VERSION ""

NS_ :

BS_:

BU_: DCU ACM
VAL_TABLE_ J1939_8bit 255 "Not Available" 254 "Fault" 253 "Reserved" 252 "Reserved" 251 "Reserved" ;
VAL_TABLE_ EDR_eCall_Active 7 "Not available" 6 "Fault" 5 "Reserved" 4 "Reserved" 3 "Reserved" 2 "On - eCall triggered" 1 "On - eCall not triggered" 0 "Off" ;
VAL_TABLE_ EDR_LwdsState 7 "Not available" 6 "Fault" 5 "Reserved" 4 "Reserved" 3 "Warning Right" 2 "Warning Left" 1 "On but not warning" 0 "Off" ;
VAL_TABLE_ EDR_Cruise_Control_Active 7 "Not Available" 6 "Fault" 5 "Reserved" 4 "Reserved" 3 "Reserved" 2 "On but not controlling" 1 "Activly Controlling" 0 "Off" ;
VAL_TABLE_ EDR_TPMSLampState 3 "Fault" 2 "Lamp Flashing" 1 "Lamp On" 0 "Lamp Off" ;
VAL_TABLE_ EDR_StrWhAng 65535 "sna" 65534 "error" ;
VAL_TABLE_ EDR_AEbState 15 "na / not installed" 14 "error indication" 8 "sys perf and/or sensitivity ltd" 7 "emergency braking active" 6 "collision warning with braking" 5 "collision warning active" 4 "driver overrides system" 3 "ready and activated" 2 "sys ready and activated" 1 "sys temp NA" 0 "sys not ready" ;
VAL_TABLE_ EDR_TCsStatus 3 "TCS off - TCS failure" 2 "Veh not equipped with TCS" 1 " TCS OFF system passive request" 0 "TCS fully available" ;
VAL_TABLE_ EDR_TCsActive 1 "TCs interv by ESP sys MFL ON" 0 "No TCs intervention MFL OFF" ;
VAL_TABLE_ EDR_ESpStatus 3 "ESP off - ESP failure" 2 "Veh not equipped with ESP" 1 "ESP OFF system passive request" 0 "ESP fully available" ;
VAL_TABLE_ EDR_ESpActive 1 "ESP interv actv MFL is BLINKING" 0 "No ESP intervention MFL OFF" ;
VAL_TABLE_ EDR_ABsStatus 2 "ABS off -  failure at ABS/ESP" 0 "ABS fully available" ;
VAL_TABLE_ EDR_ABsActive 1 "ABS intrvntn by ABS/ESP is actv" 0 "No ABS intervention by ABS/ESP" ;
VAL_TABLE_ EDR_AirbagLampState 2 "Not Available" 1 "Airbag Warning Lamp On" 0 "No Lamp" ;
VAL_TABLE_ EDR_RecupBrakeState 1 "Recuperation Enable" 0 "Recuperation Disable" ;
VAL_TABLE_ EDR_BrakePedalPressed 3 "Faulty" 2 "PedalPressed" 1 "NotPressed" 0 "NotUsed" ;

BO_ 3221225472 VECTOR__INDEPENDENT_SIG_MSG: 0 Vector__XXX
 SG_ TCSActive : 0|2@1+ (1,0) [0|1] "" Vector__XXX

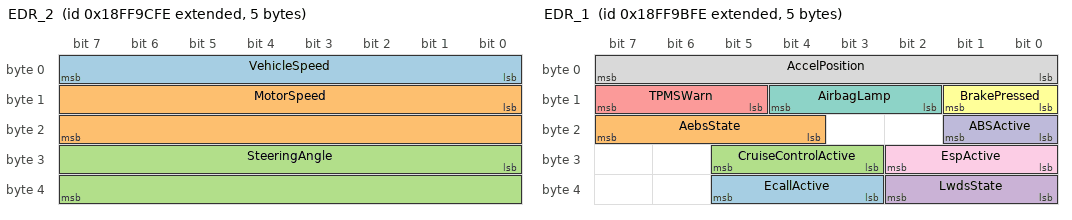
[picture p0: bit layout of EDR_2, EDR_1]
BO_ 2566888702 EDR_2: 5 DCU
 SG_ VehicleSpeed : 0|8@1+ (1,0) [0|250] "kmh"  ACM
 SG_ MotorSpeed : 8|16@1+ (1,-32127) [-32127|32128] "rpm"  ACM
 SG_ SteeringAngle : 24|16@1+ (0.0009765625,-31.374) [-31.374|31.374] "rad"  ACM

BO_ 2566888446 EDR_1: 5 DCU
 SG_ EcallActive : 35|3@1- (1,0) [0|0] ""  ACM
 SG_ AebsState : 20|4@1+ (1,0) [0|15] ""  ACM
 SG_ CruiseControlActive : 27|3@1- (1,0) [0|0] ""  ACM
 SG_ LwdsState : 32|3@1- (1,0) [0|0] ""  ACM
 SG_ TPMSWarn : 13|3@1- (1,0) [-4|3] ""  ACM
 SG_ BrakePressed : 8|2@1+ (1,0) [0|3] ""  ACM
 SG_ AirbagLamp : 10|3@1+ (1,0) [0|2] ""  ACM
 SG_ AccelPosition : 0|8@1+ (0.4,0) [0|100] "%"  ACM
 SG_ EspActive : 24|3@1+ (1,0) [0|1] ""  ACM
 SG_ ABSActive : 16|2@1+ (1,0) [0|1] ""  ACM

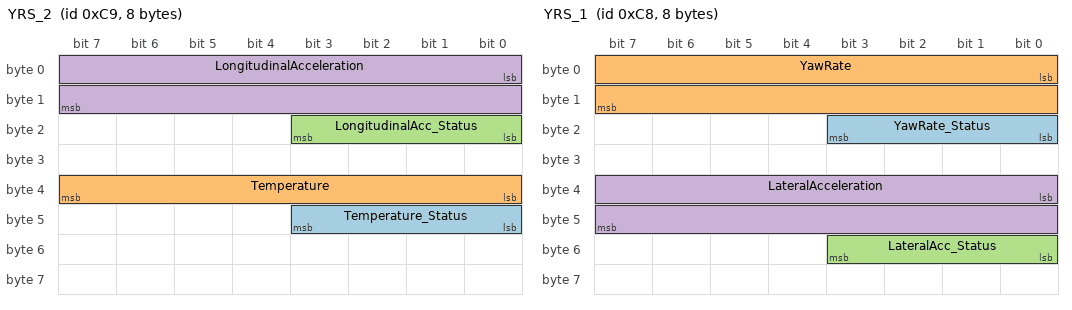
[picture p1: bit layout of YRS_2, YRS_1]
BO_ 201 YRS_2: 8 ACM
 SG_ Temperature_Status : 40|4@1+ (1,0) [0|15] "" Vector__XXX
 SG_ Temperature : 32|8@1+ (1,-68) [-68|186] "¡É" Vector__XXX
 SG_ LongitudinalAcc_Status : 16|4@1+ (1,0) [0|15] "" Vector__XXX
 SG_ LongitudinalAcceleration : 0|16@1+ (0.000127465,-4.17677312) [-4.17677312|4.17651819] "g" Vector__XXX

BO_ 200 YRS_1: 8 ACM
 SG_ YawRate_Status : 16|4@1+ (1,0) [0|15] "" Vector__XXX
 SG_ YawRate : 0|16@1+ (0.005,-163.84) [-163.84|163.83] "¢ª/s" Vector__XXX
 SG_ LateralAcc_Status : 48|4@1+ (1,0) [0|15] "" Vector__XXX
 SG_ LateralAcceleration : 32|16@1+ (0.000127465,-4.17677312) [-4.17677312|4.17651819] "g" Vector__XXX

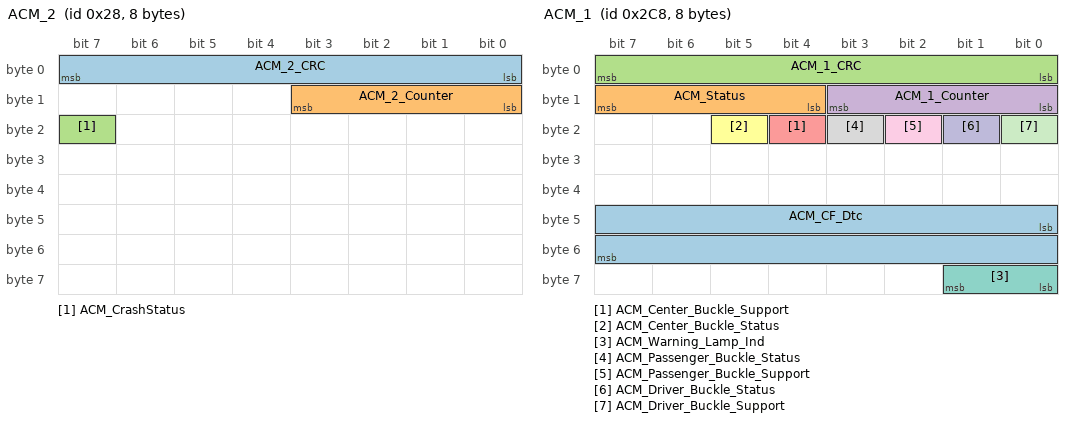
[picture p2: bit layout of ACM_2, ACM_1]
BO_ 40 ACM_2: 8 ACM
 SG_ ACM_2_CRC : 0|8@1+ (1,0) [0|0] "" Vector__XXX
 SG_ ACM_2_Counter : 8|4@1+ (1,0) [0|0] "" Vector__XXX
 SG_ ACM_CrashStatus : 23|1@1+ (1,0) [0|1] "" Vector__XXX

BO_ 712 ACM_1: 8 ACM
 SG_ ACM_CF_Dtc : 40|16@1+ (1,0) [0|0] "" Vector__XXX
 SG_ ACM_Status : 12|4@1+ (1,0) [0|0] "" Vector__XXX
 SG_ ACM_1_CRC : 0|8@1+ (1,0) [0|0] "" Vector__XXX
 SG_ ACM_1_Counter : 8|4@1+ (1,0) [0|0] "" Vector__XXX
 SG_ ACM_Center_Buckle_Support : 20|1@1+ (1,0) [0|1] "" Vector__XXX
 SG_ ACM_Center_Buckle_Status : 21|1@1+ (1,0) [0|1] "" Vector__XXX
 SG_ ACM_Warning_Lamp_Ind : 56|2@1+ (1,0) [0|3] "" Vector__XXX
 SG_ ACM_Passenger_Buckle_Status : 19|1@1+ (1,0) [0|1] "" Vector__XXX
 SG_ ACM_Passenger_Buckle_Support : 18|1@1+ (1,0) [0|1] "" Vector__XXX
 SG_ ACM_Driver_Buckle_Status : 17|1@1+ (1,0) [0|1] "" Vector__XXX
 SG_ ACM_Driver_Buckle_Support : 16|1@1+ (1,0) [0|1] "" Vector__XXX

CM_ "$File: //depot/auto/dbc/Third_party_components/Mobis/ACU_Arrival/0.0.3.0/ACU_Arrival.dbc $
$Change: 215989 $
$DateTime: 2024/08/21 10:14:39 $
$Revision: #1 $";
CM_ BO_ 3221225472 "This is a message for not used signals, created by Vector CANdb++ DBC OLE DB Provider.";
CM_ BO_ 201 "[P] Periodic";
CM_ SG_ 201 Temperature_Status "Init value : Initialization is running
0000B (Temperature in range of IMU sensor operating)
0001B (Temperature out range of IMU sensor operating)
0010B (Initialization is running)
1000B (Temperature sensor failure)";
CM_ SG_ 201 Temperature "Init value  :  0 (44h)
Error value : FFh
Range  : -68¡ÆC ~ +186¡ÆC = 00h .. FEh, 1 [¡ÆC/digit] ";
CM_ SG_ 201 LongitudinalAcc_Status "Init value :  Initialization is running
000B (No failure)
0001B (failure) 
0010B (Initialization is running)";
CM_ SG_ 201 LongitudinalAcceleration "Init value  :  0 (8000h)
Error value : FFFFh
Range  : -4.1768g..4.1765g = 0000h..FFFEh, 0.000127465 [g/digit]";
CM_ BO_ 200 "[P] Periodic";
CM_ SG_ 200 YawRate_Status "Init value :  Initialization is running
000B (No failure)
0001B (failure) 
0010B (Initialization is running)";
CM_ SG_ 200 YawRate "Init value  :  0 (8000h)
Error value : FFFFh
Range  : -163.84..163.83 ¢ª/s =  0000h..FFFEh, 0.005[¢ª/s/digit]";
CM_ SG_ 200 LateralAcc_Status "Init value :  Initialization is running
000B (No failure)
0001B (failure) 
0010B (Initialization is running)";
CM_ SG_ 200 LateralAcceleration "Init value  :  0 (8000h)
Error value : FFFFh
Range  : -4.1768g..4.1765g = 0000h..FFFEh, 0.000127465 [g/digit]";
CM_ BO_ 40 "Switching Cycle Time to 10ms for 30s when crash detected";
CM_ SG_ 40 ACM_2_CRC "AUTOSAR E2E Profile variant 1A";
CM_ SG_ 40 ACM_CrashStatus "0B (Crash Active time expired)
1B (Crash Active time started)";
CM_ BO_ 712 "[P] Periodic";
CM_ SG_ 712 ACM_CF_Dtc "0x18D2 : Internal DTC(Latch)
0x18E0~0x18E7 : Internal DTC";
CM_ SG_ 712 ACM_Status "0x0 Default
0x1 Initializing (It takes about 6s)
0x2 Internal (B18D200, B18EX00)
0x3 Active No fault or only external fault
0x4 End of Line Not Complete
0x5 Crash Locked

priority 4 = 5 > 1 > 2 > 3";
CM_ SG_ 712 ACM_1_CRC "AUTOSAR E2E Profile variant 1A";
CM_ SG_ 712 ACM_1_Counter "AUTOSAR E2E Profile variant 1A";
CM_ SG_ 712 ACM_Center_Buckle_Support "0B (Not Supported)
1B (Supported)";
CM_ SG_ 712 ACM_Center_Buckle_Status "Init value : Latched
0B (Not Latched)
1B (Latched)";
CM_ SG_ 712 ACM_Warning_Lamp_Ind "0x0 (WL off)
0x1 (WL on)
0x2 (WL flash)
0x3 (reserved)";
CM_ SG_ 712 ACM_Passenger_Buckle_Status "Init value : Latched
0B (Not Latched)
1B (Latched)";
CM_ SG_ 712 ACM_Passenger_Buckle_Support "0B (Not Supported)
1B (Supported)";
CM_ SG_ 712 ACM_Driver_Buckle_Status "Init value : Latched
0B (Not Latched)
1B (Latched)";
CM_ SG_ 712 ACM_Driver_Buckle_Support "0B (Not Supported)
1B (Supported)";
BA_DEF_ BU_  "ACM_Tx_Version" STRING ;
BA_DEF_ SG_  "SigType" ENUM  "Default","Range","RangeSigned","ASCII","Discrete","Control","ReferencePGN","DTC","StringDelimiter","StringLength","StringLengthControl";
BA_DEF_ SG_  "GenSigEVName" STRING ;
BA_DEF_ SG_  "GenSigILSupport" ENUM  "No","Yes";
BA_DEF_ SG_  "GenSigSendType" ENUM  "Cyclic","OnWrite","OnWriteWithRepetition","OnChange","OnChangeWithRepetition","IfActive","IfActiveWithRepetition","NoSigSendType";
BA_DEF_ BO_  "GenMsgCycleTimeFast" INT 0 3600000;
BA_DEF_ SG_  "GenSigStartValue" INT 0 2147483647;
BA_DEF_ BO_  "GenMsgILSupport" ENUM  "No","Yes";
BA_DEF_ BU_  "NmStationAddress" INT 0 255;
BA_DEF_ BO_  "GenMsgSendType" ENUM  "cyclic","NotUsed","IfActive","NotUsed","NotUsed","NotUsed","NotUsed","NotUsed","noMsgSendType";
BA_DEF_ BO_  "GenMsgRequestable" INT 0 1;
BA_DEF_ BO_  "GenMsgCycleTime" INT 0 3600000;
BA_DEF_  "Manufacturer" STRING ;
BA_DEF_  "Baudrate" INT 50000 1000000;
BA_DEF_  "BusType" STRING ;
BA_DEF_  "DBName" STRING ;
BA_DEF_  "ProtocolType" STRING ;
BA_DEF_ BO_  "VFrameFormat" ENUM  "StandardCAN","ExtendedCAN","reserved","J1939PG";
BA_DEF_ BO_  "Producer" STRING ;
BA_DEF_DEF_  "ACM_Tx_Version" "need to update";
BA_DEF_DEF_  "SigType" "Default";
BA_DEF_DEF_  "GenSigEVName" "Env@Nodename_@Signame";
BA_DEF_DEF_  "GenSigILSupport" "Yes";
BA_DEF_DEF_  "GenSigSendType" "NoSigSendType";
BA_DEF_DEF_  "GenMsgCycleTimeFast" 0;
BA_DEF_DEF_  "GenSigStartValue" 0;
BA_DEF_DEF_  "GenMsgILSupport" "Yes";
BA_DEF_DEF_  "NmStationAddress" 254;
BA_DEF_DEF_  "GenMsgSendType" "noMsgSendType";
BA_DEF_DEF_  "GenMsgRequestable" 1;
BA_DEF_DEF_  "GenMsgCycleTime" 0;
BA_DEF_DEF_  "Manufacturer" "ARRIVAL";
BA_DEF_DEF_  "Baudrate" 500000;
BA_DEF_DEF_  "BusType" "CAN";
BA_DEF_DEF_  "DBName" "";
BA_DEF_DEF_  "ProtocolType" "J1939";
BA_DEF_DEF_  "VFrameFormat" "J1939PG";
BA_ "DBName" "EDR_MOBIS";
BA_ "ACM_Tx_Version" BU_ ACM "1.5";
BA_ "NmStationAddress" BU_ ACM 0;
BA_ "GenMsgCycleTime" BO_ 2566888702 200;
BA_ "GenMsgCycleTime" BO_ 2566888446 200;
BA_ "GenMsgCycleTime" BO_ 201 10;
BA_ "VFrameFormat" BO_ 201 0;
BA_ "GenMsgSendType" BO_ 201 0;
BA_ "GenMsgCycleTime" BO_ 200 10;
BA_ "VFrameFormat" BO_ 200 0;
BA_ "GenMsgSendType" BO_ 200 0;
BA_ "GenMsgSendType" BO_ 40 2;
BA_ "VFrameFormat" BO_ 40 0;
BA_ "GenMsgCycleTimeFast" BO_ 40 10;
BA_ "GenMsgCycleTime" BO_ 40 500;
BA_ "GenMsgCycleTime" BO_ 712 100;
BA_ "VFrameFormat" BO_ 712 0;
BA_ "GenMsgSendType" BO_ 712 0;
BA_ "GenSigStartValue" SG_ 2566888702 MotorSpeed 32127;
BA_ "GenSigStartValue" SG_ 2566888702 SteeringAngle 32126.976;
BA_ "GenSigStartValue" SG_ 201 Temperature_Status 2;
BA_ "GenSigStartValue" SG_ 201 Temperature 68;
BA_ "GenSigStartValue" SG_ 201 LongitudinalAcc_Status 2;
BA_ "GenSigStartValue" SG_ 201 LongitudinalAcceleration 32768;
BA_ "GenSigStartValue" SG_ 200 YawRate_Status 2;
BA_ "GenSigStartValue" SG_ 200 YawRate 32768;
BA_ "GenSigStartValue" SG_ 200 LateralAcc_Status 2;
BA_ "GenSigStartValue" SG_ 200 LateralAcceleration 32768;
BA_ "GenSigStartValue" SG_ 40 ACM_2_CRC 241;
BA_ "GenSigStartValue" SG_ 712 ACM_1_CRC 208;
BA_ "GenSigStartValue" SG_ 712 ACM_Center_Buckle_Status 1;
BA_ "GenSigStartValue" SG_ 712 ACM_Warning_Lamp_Ind 1;
BA_ "GenSigStartValue" SG_ 712 ACM_Passenger_Buckle_Status 1;
BA_ "GenSigStartValue" SG_ 712 ACM_Driver_Buckle_Status 1;
BA_ "Producer" BO_ 2566888446 "SFT";
BA_ "Producer" BO_ 2566888702 "SFT";
VAL_ 3221225472 TCSActive 3 "Not available" 2 "Fault" 1 "Active" 0 "Not Active" ;
VAL_ 2566888702 VehicleSpeed 255 "Not Available" 254 "Fault" 253 "Reserved" 252 "Reserved" 251 "Reserved" ;
VAL_ 2566888446 EcallActive 7 "Not available" 6 "Fault" 5 "Reserved" 4 "Reserved" 3 "Reserved" 2 "On - eCall triggered" 1 "On - eCall not triggered" 0 "Off" ;
VAL_ 2566888446 AebsState 13 "Reserved" 12 "Reserved" 11 "Reserved" 10 "Reserved" 9 "Reserved" 15 "Not Available" 14 "Fault" 8 "Reserved" 7 "Emergency Braking Active" 6 "Warning with braking active" 5 "Warning Active" 4 "Driver overrides system" 3 "Ready and activated" 2 "Deactivated by driver" 1 "Temporarily not available" 0 "Not Ready" ;
VAL_ 2566888446 CruiseControlActive 7 "Not Available" 6 "Fault" 5 "Reserved" 4 "Reserved" 3 "Reserved" 2 "On but not controlling" 1 "Activly Controlling" 0 "Off" ;
VAL_ 2566888446 LwdsState 7 "Not available" 6 "Fault" 5 "Reserved" 4 "Reserved" 3 "Warning Right" 2 "Warning Left" 1 "On but not warning" 0 "Off" ;
VAL_ 2566888446 TPMSWarn 7 "Not Available" 6 "Fault" 5 "Reserved" 4 "Reserved" 3 "Reserved" 2 "Lamp Flashing" 1 "Lamp On" 0 "Lamp Off" ;
VAL_ 2566888446 BrakePressed 3 "Not Available" 2 "Fault" 1 "Pressed" 0 "Not Pressed" ;
VAL_ 2566888446 AirbagLamp 7 "Not Available" 6 "Fault" 5 "Reserved" 4 "Reserved" 3 "Reserved" 2 "Lamp Flashing" 1 "Lamp On" 0 "Lamp Off" ;
VAL_ 2566888446 AccelPosition 255 "Not Available" 254 "Fault" 253 "Reserved" 252 "Reserved" 251 "Reserved" ;
VAL_ 2566888446 EspActive 7 "Not Available" 6 "Fault" 5 "Reserved" 4 "Reserved" 3 "Reserved" 2 "ESP Intervening" 1 "On" 0 "Off" ;
VAL_ 2566888446 ABSActive 3 "Not available" 2 "Fault" 1 "Active" 0 "Not Active" ;
VAL_ 201 Temperature_Status 8 "Temperature sensor failure" 2 "Initialization is running" 1 "Temperature out of range -40~85c" 0 "Temperature in range of -40~85c" ;
VAL_ 201 LongitudinalAcc_Status 8 "reserved" 1 "Signal Failure" 2 "Initialization is running" 4 "reserved" 0 "Signal in specification" ;
VAL_ 200 YawRate_Status 8 "reserved" 1 "Signal Failure" 2 "Initialization is running" 4 "reserved" 0 "Signal in specification" ;
VAL_ 200 LateralAcc_Status 8 "reserved" 1 "Signal Failure" 2 "Initialization is running" 4 "reserved" 0 "Signal in specification" ;
VAL_ 40 ACM_CrashStatus 1 "Crash Active time started" 0 "Crash Active time expired" ;
VAL_ 712 ACM_Status 7 "Not used" 6 "Not used" 5 "Crash Locked" 4 "End of Line Not Complete" 3 "Active (incl. external fault)" 2 "Internal Falult" 1 "Initializing (~6s)" 0 "Default" ;
VAL_ 712 ACM_Center_Buckle_Support 1 "Supported" 0 "Not Supported" ;
VAL_ 712 ACM_Center_Buckle_Status 1 "Latched" 0 "Not Latched" ;
VAL_ 712 ACM_Warning_Lamp_Ind 3 "Not used" 2 "Warning Lamp Flash" 1 "Warning Lamp On" 0 "Warning Lamp Off" ;
VAL_ 712 ACM_Passenger_Buckle_Status 1 "Latched" 0 "Not Latched" ;
VAL_ 712 ACM_Passenger_Buckle_Support 1 "Supported" 0 "Not Supported" ;
VAL_ 712 ACM_Driver_Buckle_Status 1 "Latched" 0 "Not Latched" ;
VAL_ 712 ACM_Driver_Buckle_Support 1 "Supported" 0 "Not Supported" ;
